# CH32V305xx register map
Vendor: WCH Ltd.; File version: 1.2
Registers are 32-bit, read-write, reset 0x0 unless marked. A register's access mark holds for its fields unless they carry their own. Offsets are from the block's base; [hi:lo] are bit positions; {n}, {i} and the like mark numbered series.

## DAC — Digital to analog converter
Base 0x40007400
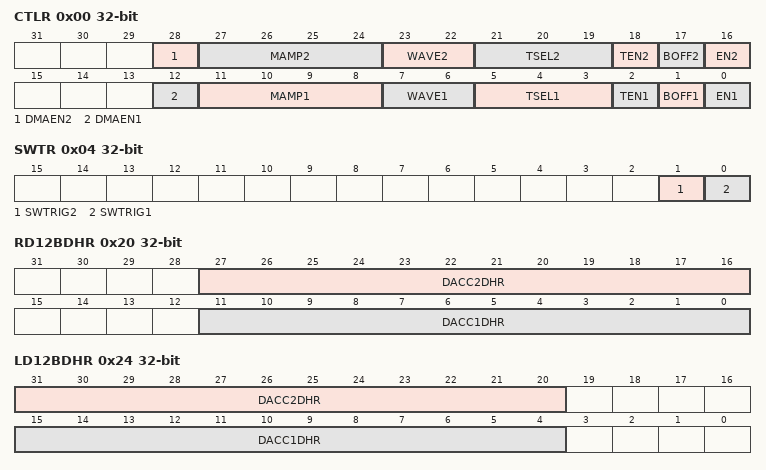
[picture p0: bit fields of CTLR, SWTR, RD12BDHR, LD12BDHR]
0x00 CTLR — Control register (DAC_CR)
  [28] DMAEN2 — DAC channel2 DMA enable
  [27:24] MAMP2 — DAC channel2 mask/amplitude selector
  [23:22] WAVE2 — DAC channel2 noise/triangle wave generation enable
  [21:19] TSEL2 — DAC channel2 trigger selection
  [18] TEN2 — DAC channel2 trigger enable
  [17] BOFF2 — DAC channel2 output buffer disable
  [16] EN2 — DAC channel2 enable
  [12] DMAEN1 — DAC channel1 DMA enable
  [11:8] MAMP1 — DAC channel1 mask/amplitude selector
  [7:6] WAVE1 — DAC channel1 noise/triangle wave generation enable
  [5:3] TSEL1 — DAC channel1 trigger selection
  [2] TEN1 — DAC channel1 trigger enable
  [1] BOFF1 — DAC channel1 output buffer disable
  [0] EN1 — DAC channel1 enable
0x04 SWTR wo — DAC software trigger register (DAC_SWTRIGR)
  [1] SWTRIG2 — DAC channel2 software trigger
  [0] SWTRIG1 — DAC channel1 software trigger
0x08 R12BDHR1 — DAC channel1 12-bit right-aligned data holding register(DAC_DHR12R1)
  [11:0] DACC1DHR — DAC channel1 12-bit right-aligned data
0x0C L12BDHR1 — DAC channel1 12-bit left aligned data holding register (DAC_DHR12L1)
  [15:4] DACC1DHR — DAC channel1 12-bit left-aligned data
0x10 R8BDHR1 — DAC channel1 8-bit right aligned data holding register (DAC_DHR8R1)
  [7:0] DACC1DHR — DAC channel1 8-bit right-aligned data
0x14 R12BDHR2 — DAC channel2 12-bit right aligned data holding register (DAC_DHR12R2)
  [11:0] DACC2DHR — DAC channel2 12-bit right-aligned data
0x18 L12BDHR2 — DAC channel2 12-bit left aligned data holding register (DAC_DHR12L2)
  [15:4] DACC2DHR — DAC channel2 12-bit left-aligned data
0x1C R8BDHR2 — DAC channel2 8-bit right-aligned data holding register (DAC_DHR8R2)
  [7:0] DACC2DHR — DAC channel2 8-bit right-aligned data
0x20 RD12BDHR — Dual DAC 12-bit right-aligned data holding register (DAC_DHR12RD), Bits 31:28 Reserved, Bits 15:12 Reserved
  [27:16] DACC2DHR — DAC channel2 12-bit right-aligned data
  [11:0] DACC1DHR — DAC channel1 12-bit right-aligned data
0x24 LD12BDHR — DUAL DAC 12-bit left aligned data holding register (DAC_DHR12LD), Bits 19:16 Reserved, Bits 3:0 Reserved
  [31:20] DACC2DHR — DAC channel2 12-bit right-aligned data
  [15:4] DACC1DHR — DAC channel1 12-bit left-aligned data
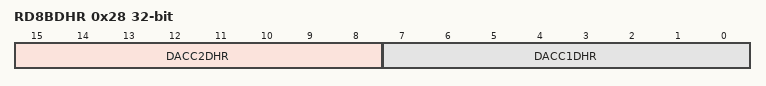
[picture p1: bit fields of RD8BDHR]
0x28 RD8BDHR — DUAL DAC 8-bit right aligned data holding register (DAC_DHR8RD), Bits 31:16 Reserved
  [15:8] DACC2DHR — DAC channel2 8-bit right-aligned data
  [7:0] DACC1DHR — DAC channel1 8-bit right-aligned data
0x2C DOR1 ro — DAC channel1 data output register (DAC_DOR1)
  [11:0] DACC1DOR — DAC channel1 data output
0x30 DOR2 ro — DAC channel2 data output register (DAC_DOR2)
  [11:0] DACC2DOR — DAC channel2 data output

## PWR — Power control
Base 0x40007000
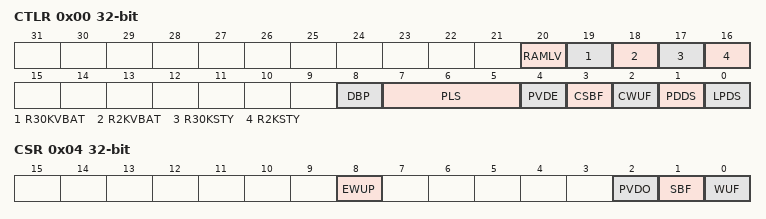
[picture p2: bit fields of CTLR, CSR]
0x00 CTLR — Power control register (PWR_CTRL)
  [20] RAMLV — Ram LV Enable
  [19] R30KVBAT — VBAT 30k ram enable
  [18] R2KVBAT — VBAT 30k ram enable
  [17] R30KSTY — standby 30k ram enable
  [16] R2KSTY — standby 2k ram enable
  [8] DBP — Disable Backup Domain write protection
  [7:5] PLS — PVD Level Selection
  [4] PVDE — Power Voltage Detector Enable
  [3] CSBF — Clear STANDBY Flag
  [2] CWUF — Clear Wake-up Flag
  [1] PDDS — Power Down Deep Sleep
  [0] LPDS — Low Power Deep Sleep
0x04 CSR access per field — Power control register (PWR_CSR)
  [8] EWUP rw — Enable WKUP pin
  [2] PVDO ro — PVD Output
  [1] SBF ro — STANDBY Flag
  [0] WUF ro — Wake-Up Flag

## EXTEND — Extend configuration
Base 0x40023800
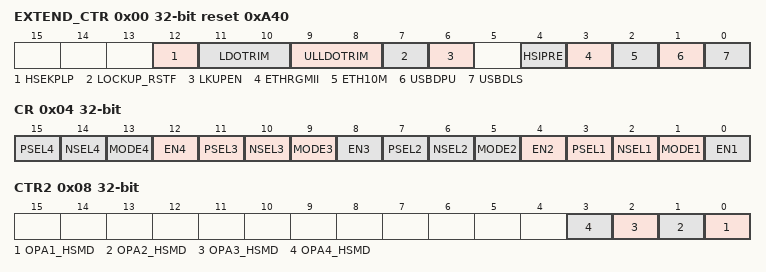
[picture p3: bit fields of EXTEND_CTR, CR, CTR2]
0x00 EXTEND_CTR access per field reset 0xA40 — EXTEND register
  [12] HSEKPLP rw — HSE_KEEP_LP
  [11:10] LDOTRIM rw
  [9:8] ULLDOTRIM rw
  [7] LOCKUP_RSTF read/clear — LOCKUP RESET
  [6] LKUPEN rw — LOCKUP_Eable
  [4] HSIPRE rw — Whether HSI is divided
  [3] ETHRGMII rw — ETH RGMII Enable
  [2] ETH10M rw — ETH 10M Enable
  [1] USBDPU rw — USBD pullup Enable
  [0] USBDLS rw — USBD Lowspeed Enable
0x04 CR — OPA Control register
  [4n-1] PSEL{n} (n=1..4) — OPA PSEL{n}
  [4n-2] NSEL{n} (n=1..4) — OPA NSEL{n}
  [4n-3] MODE{n} (n=1..4) — OPA MODE{n}
  [12] EN4 — OPA Enable4
  [8] EN3 — OPA Eable3
  [4] EN2 — OPA Enable2
  [0] EN1 — OPA Enable1
0x08 CTR2 — EXTEND register 2
  [n-1] OPA{n}_HSMD (n=1..4) — OPA{n} high-speed mode enable
